# PAT0_CFG_MMRS register map
Vendor: Texas Instruments
Peripheral module from a debugger description file (folder J7ES).
Registers are 32-bit, read-only, reset values left out (the file's numbers can be read two ways) unless marked. A register's access mark holds for its fields unless they carry their own. Offsets are as the file gives them; lines under a group give offsets from that group; [hi:lo] are bit positions; {n}, {i} and the like mark numbered series; 'fields as' and 'values as' point back to an identical list; <NAME> marks a mode.

## PAT0_CFG_MMRS
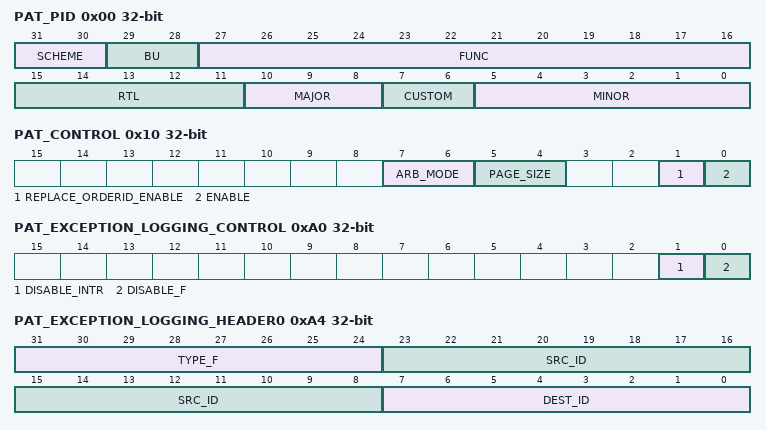
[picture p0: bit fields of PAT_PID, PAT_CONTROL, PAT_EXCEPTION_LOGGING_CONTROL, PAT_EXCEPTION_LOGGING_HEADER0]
0x00 PAT_PID — The Revision Register contains the major and minor revisions for the module.
  [31:30] SCHEME — PID register scheme
  [29:28] BU
  [27:16] FUNC — Module ID
  [15:11] RTL — RTL revision. Will vary depending on release.
  [10:8] MAJOR — Major revision
  [7:6] CUSTOM
  [5:0] MINOR — Minor revision
0x04 PAT_CONFIG — The Config Register contains the configuration values for the module.
  [31:0] PAGES — Number of pages 4000h: PAT0-2 800h: PAT3-4
0x10 PAT_CONTROL access per field — The Control Register contains controls for the PAT.
  [7:6] ARB_MODE rw — Arbitration mode. 0 = updates first. 1 = reserved. 2 = round robin. 3 = reserved.
  [5:4] PAGE_SIZE rw — Page Size. 0 = 4KB. 1 = 16KB. 2 = 64KB. 3 = 1MB.
  [1] REPLACE_ORDERID_ENABLE ro — Globally enable the replace orderid feature allowing a hypervisor or OS to globally disable the feature if applications or VMs should not be able to modify orderid values. The page based enables are used if globally enabled and are always ignored if globally disabled. 0 = disabled. 1 = enabled
  [0] ENABLE rw — Enable bit. 0 = disabled. 1 = enabled
0x84 PAT_DESTINATION_ID rw — The Destination ID Register defines the destination ID value for error messages.
  [7:0] DEST_ID — The destination ID.
0xA0 PAT_EXCEPTION_LOGGING_CONTROL rw — The Exception Logging Control Register controls the exception logging.
  [1] DISABLE_INTR — Disables logging interrupt when set.
  [0] DISABLE_F — Disables logging when set.
0xA4 PAT_EXCEPTION_LOGGING_HEADER0 — The Exception Logging Header 0 Register contains the first word of the header.
  [31:24] TYPE_F — Type. 5 = PAT.
  [23:8] SRC_ID — Source ID.
  [7:0] DEST_ID — Destination ID.
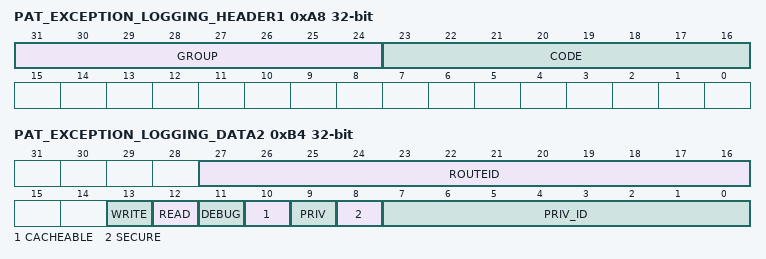
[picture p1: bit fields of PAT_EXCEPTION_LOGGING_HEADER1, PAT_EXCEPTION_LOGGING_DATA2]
0xA8 PAT_EXCEPTION_LOGGING_HEADER1 — The Exception Logging Header 1 Register contains the second word of the header.
  [31:24] GROUP
  [23:16] CODE — Code. 1 = Boundary crossing error. 2 = Page not enabled error.
0xAC PAT_EXCEPTION_LOGGING_DATA0 — The Exception Logging Data 0 Register contains the first word of the data.
  [31:0] ADDR_L — Address lower 32 bits.
0xB0 PAT_EXCEPTION_LOGGING_DATA1 — The Exception Logging Data 1 Register contains the second word of the data.
  [15:0] ADDR_H — Address upper 16 bits.
0xB4 PAT_EXCEPTION_LOGGING_DATA2 — The Exception Logging Data 2 Register contains the third word of the data.
  [27:16] ROUTEID, [13] WRITE, [12] READ, [11] DEBUG, [10] CACHEABLE, [9] PRIV, [8] SECURE, [7:0] PRIV_ID
0xB8 PAT_EXCEPTION_LOGGING_DATA3 — The Exception Logging Data 3 Register contains the third word of the data. Reading this register will clear the error pending bit.
  [9:0] BYTECNT — Byte count.
0xC0 PAT_EXCEPTION_PEND_SET access not given — The Exception Logging Interrupt Pending Set Register allows to set the pend signal.
  [0] PEND_SET — Write a 1 to set the exception pend signal. (access RW1S)
0xC4 PAT_EXCEPTION_PEND_CLEAR access not given — The Exception Logging Interrupt Pending Clear Register allows to clear the pend signal.
  [0] PEND_CLR — Write a 1 to clear the exception pend signal. (access RW1C)
0xC8 PAT_EXCEPTION_ENABLE_SET access not given — The Exception Logging Interrupt Enable Set Register allows to set the interrupt enable signal.
  [0] ENABLE_SET — Write a 1 to set the exception interrupt enable signal. (access RW1S)
0xCC PAT_EXCEPTION_ENABLE_CLEAR access not given — The Exception Logging Interrupt Enable Clear Register allows to clear the interrupt enable signal.
  [0] ENABLE_CLR — Write a 1 to clear the exception interrupt enable signal. (access RW1C)
0xD0 PAT_EOI_REG rw — EOI Register The EOI register is used to re-trigger the pulse interrupt signal to ensure that any nested interrupt events are serviced. The software interrupt handler must write to the EOI register at the end of the current interrupt processing routine, so that new events can re-trigger the pulse interrupt signal again. For level interrupt signals the EOI register is not functional and must not be used.
  [15:0] EOI_WR — EOI Register
